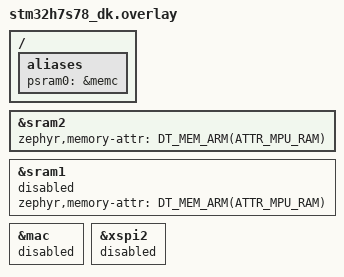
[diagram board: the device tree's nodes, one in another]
/*
 * Copyright (c) 2025 STMicroelectronics
 *
 * SPDX-License-Identifier: Apache-2.0
 */

/ {
	aliases {
		psram0 = &memc;
	};
};

&sram2 {
	zephyr,memory-attr = <DT_MEM_ARM(ATTR_MPU_RAM)>;
	status = "okay";
};

&sram1 {
	zephyr,memory-attr = <DT_MEM_ARM(ATTR_MPU_RAM)>;
	status = "disabled";
};

&mac {
	/*
	 * mac is disabled for this test since the ethernet driver that gets
	 * enabled by this node consumes the sram1 node thus failing this test
	 */
	status = "disabled";
};

&xspi2 {
	status = "disabled";
};
